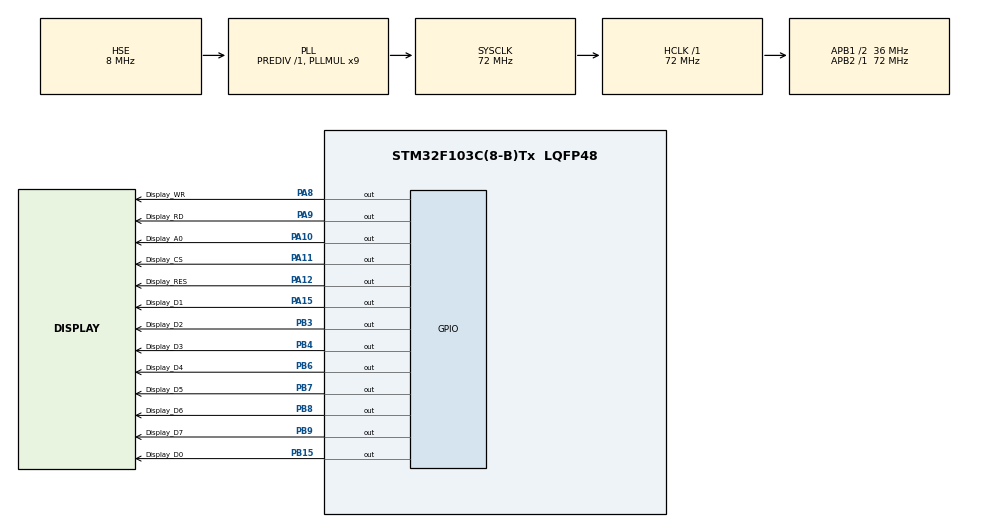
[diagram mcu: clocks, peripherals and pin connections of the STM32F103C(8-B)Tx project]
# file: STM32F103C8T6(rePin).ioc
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Mcu.Family=STM32F1
Mcu.Name=STM32F103C(8-B)Tx
Mcu.Package=LQFP48
NVIC.PriorityGroup=NVIC_PRIORITYGROUP_4
NVIC.RTC_Alarm_IRQn=true\:0\:0\:false\:false\:true\:true\:true
NVIC.RTC_IRQn=true\:0\:0\:false\:false\:true\:true\:true
PA10.GPIO_Label=Display_A0
PA10.GPIO_ModeDefaultOutputPP=GPIO_MODE_OUTPUT_OD
PA10.GPIO_PuPd=GPIO_NOPULL
PA10.Signal=GPIO_Output
PA11.GPIO_Label=Display_CS
PA11.GPIO_ModeDefaultOutputPP=GPIO_MODE_OUTPUT_OD
PA11.GPIO_PuPd=GPIO_NOPULL
PA11.Signal=GPIO_Output
PA12.GPIO_Label=Display_RES
PA12.GPIO_ModeDefaultOutputPP=GPIO_MODE_OUTPUT_OD
PA12.GPIO_PuPd=GPIO_NOPULL
PA12.Signal=GPIO_Output
PA13.Mode=Serial_Wire
PA13.Signal=SYS_JTMS-SWDIO
PA14.Mode=Serial_Wire
PA14.Signal=SYS_JTCK-SWCLK
PA15.GPIO_Label=Display_D1
PA15.GPIO_ModeDefaultOutputPP=GPIO_MODE_OUTPUT_OD
PA15.GPIO_PuPd=GPIO_NOPULL
PA15.Signal=GPIO_Output
PA8.GPIO_Label=Display_WR
PA8.GPIO_ModeDefaultOutputPP=GPIO_MODE_OUTPUT_OD
PA8.GPIO_PuPd=GPIO_NOPULL
PA8.Signal=GPIO_Output
PA9.GPIO_Label=Display_RD
PA9.GPIO_ModeDefaultOutputPP=GPIO_MODE_OUTPUT_OD
PA9.GPIO_PuPd=GPIO_NOPULL
PA9.Signal=GPIO_Output
PB15.GPIO_Label=Display_D0
PB15.GPIO_ModeDefaultOutputPP=GPIO_MODE_OUTPUT_OD
PB15.GPIO_PuPd=GPIO_NOPULL
PB15.Signal=GPIO_Output
PB3.GPIO_Label=Display_D2
PB3.GPIO_ModeDefaultOutputPP=GPIO_MODE_OUTPUT_OD
PB3.GPIO_PuPd=GPIO_NOPULL
PB3.Signal=GPIO_Output
PB4.GPIO_Label=Display_D3
PB4.GPIO_ModeDefaultOutputPP=GPIO_MODE_OUTPUT_OD
PB4.GPIO_PuPd=GPIO_NOPULL
PB4.Signal=GPIO_Output
PB6.GPIO_Label=Display_D4
PB6.GPIO_ModeDefaultOutputPP=GPIO_MODE_OUTPUT_OD
PB6.GPIO_PuPd=GPIO_NOPULL
PB6.Signal=GPIO_Output
PB7.GPIO_Label=Display_D5
PB7.GPIO_ModeDefaultOutputPP=GPIO_MODE_OUTPUT_OD
PB7.GPIO_PuPd=GPIO_NOPULL
PB7.Signal=GPIO_Output
PB8.GPIO_Label=Display_D6
PB8.GPIO_ModeDefaultOutputPP=GPIO_MODE_OUTPUT_OD
PB8.GPIO_PuPd=GPIO_NOPULL
PB8.Signal=GPIO_Output
PB9.GPIO_Label=Display_D7
PB9.GPIO_ModeDefaultOutputPP=GPIO_MODE_OUTPUT_OD
PB9.GPIO_PuPd=GPIO_NOPULL
PB9.Signal=GPIO_Output
PC14-OSC32_IN.Mode=LSE-External-Oscillator
PC14-OSC32_IN.Signal=RCC_OSC32_IN
PC15-OSC32_OUT.Mode=LSE-External-Oscillator
PC15-OSC32_OUT.Signal=RCC_OSC32_OUT
PD0-OSC_IN.Mode=HSE-External-Oscillator
PD0-OSC_IN.Signal=RCC_OSC_IN
PD1-OSC_OUT.Mode=HSE-External-Oscillator
PD1-OSC_OUT.Signal=RCC_OSC_OUT
ProjectManager.HeapSize=0x200
ProjectManager.StackSize=0x400
ProjectManager.TargetToolchain=MDK-ARM V5.32
RCC.AHBFreq_Value=72000000
RCC.APB1CLKDivider=RCC_HCLK_DIV2
RCC.APB1Freq_Value=36000000
RCC.APB1TimFreq_Value=72000000
RCC.APB2Freq_Value=72000000
RCC.APB2TimFreq_Value=72000000
RCC.EnbaleCSS=true
RCC.HCLKFreq_Value=72000000
RCC.PLLMUL=RCC_PLL_MUL9
RCC.PLLSourceVirtual=RCC_PLLSOURCE_HSE
RCC.RTCClockSelection=RCC_RTCCLKSOURCE_LSE
RCC.SYSCLKFreq_VALUE=72000000
RCC.SYSCLKSource=RCC_SYSCLKSOURCE_PLLCLK
RCC.USBFreq_Value=72000000
VP_RTC_VS_RTC_Activate.Mode=RTC_Enabled
board=custom

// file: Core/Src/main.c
/* USER CODE BEGIN Header */
/**
  ******************************************************************************
  * @file           : main.c
  * @brief          : Main program body
  ******************************************************************************
  * @attention
  *
  * Copyright (c) 2024 STMicroelectronics.
  * All rights reserved.
  *
  * This software is licensed under terms that can be found in the LICENSE file
  * in the root directory of this software component.
  * If no LICENSE file comes with this software, it is provided AS-IS.
  *
  ******************************************************************************
  */
/* USER CODE END Header */
#include "main.h"
#include "rtc.h"
#include "gpio.h"

/* USER CODE BEGIN Includes */
#include "sed1335.h"
/* USER CODE END Includes */

void SystemClock_Config(void);

int main(void)
{

  /* MCU Configuration--------------------------------------------------------*/

  /* Reset of all peripherals, Initializes the Flash interface and the Systick. */
  HAL_Init();

  /* Configure the system clock */
  SystemClock_Config();

  /* Initialize all configured peripherals */
  MX_GPIO_Init();
  MX_RTC_Init();

  /* Infinite loop */
  /* USER CODE BEGIN WHILE */
	GLCD_Initialize();
	//GLCD_ClearGraphic();
	//GLCD_CircleSS(80,80,60,-90,90);
	GLCD_ClearText();
	GLCD_TextGoTo(7,12);
	GLCD_WriteText("5.6 kg/cm2");
  while (1)
  {
    /* USER CODE END WHILE */

  }
}

void SystemClock_Config(void)
{
  RCC_OscInitTypeDef RCC_OscInitStruct = {0};
  RCC_ClkInitTypeDef RCC_ClkInitStruct = {0};
  RCC_PeriphCLKInitTypeDef PeriphClkInit = {0};

  /** Initializes the RCC Oscillators according to the specified parameters
  * in the RCC_OscInitTypeDef structure.
  */
  RCC_OscInitStruct.OscillatorType = RCC_OSCILLATORTYPE_HSE|RCC_OSCILLATORTYPE_LSE;
  RCC_OscInitStruct.HSEState = RCC_HSE_ON;
  RCC_OscInitStruct.HSEPredivValue = RCC_HSE_PREDIV_DIV1;
  RCC_OscInitStruct.LSEState = RCC_LSE_ON;
  RCC_OscInitStruct.HSIState = RCC_HSI_ON;
  RCC_OscInitStruct.PLL.PLLState = RCC_PLL_ON;
  RCC_OscInitStruct.PLL.PLLSource = RCC_PLLSOURCE_HSE;
  RCC_OscInitStruct.PLL.PLLMUL = RCC_PLL_MUL9;
  if (HAL_RCC_OscConfig(&RCC_OscInitStruct) != HAL_OK)
  {
    Error_Handler();
  }
  /** Initializes the CPU, AHB and APB buses clocks
  */
  RCC_ClkInitStruct.ClockType = RCC_CLOCKTYPE_HCLK|RCC_CLOCKTYPE_SYSCLK
                              |RCC_CLOCKTYPE_PCLK1|RCC_CLOCKTYPE_PCLK2;
  RCC_ClkInitStruct.SYSCLKSource = RCC_SYSCLKSOURCE_PLLCLK;
  RCC_ClkInitStruct.AHBCLKDivider = RCC_SYSCLK_DIV1;
  RCC_ClkInitStruct.APB1CLKDivider = RCC_HCLK_DIV2;
  RCC_ClkInitStruct.APB2CLKDivider = RCC_HCLK_DIV1;

  if (HAL_RCC_ClockConfig(&RCC_ClkInitStruct, FLASH_LATENCY_2) != HAL_OK)
  {
    Error_Handler();
  }
  PeriphClkInit.PeriphClockSelection = RCC_PERIPHCLK_RTC;
  PeriphClkInit.RTCClockSelection = RCC_RTCCLKSOURCE_LSE;
  if (HAL_RCCEx_PeriphCLKConfig(&PeriphClkInit) != HAL_OK)
  {
    Error_Handler();
  }
  /** Enables the Clock Security System
  */
  HAL_RCC_EnableCSS();
}

void Error_Handler(void)
{
  __disable_irq();
  while (1)
  {
  }
}
